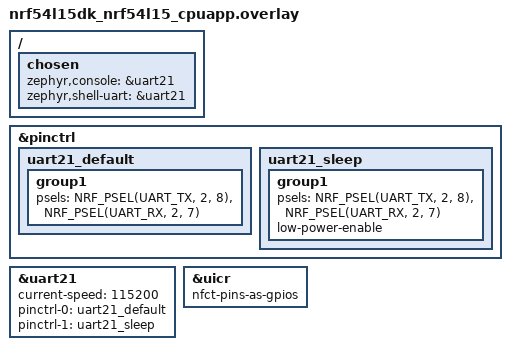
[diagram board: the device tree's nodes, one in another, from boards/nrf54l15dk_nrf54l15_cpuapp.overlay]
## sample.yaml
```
sample:
  description: Hello World sample, the simplest Zephyr
    application
  name: hello world
common:
  min_ram: 2
  min_flash: 16
  tags: introduction
  integration_platforms:
    - native_sim
  harness: console
  harness_config:
    type: one_line
    regex:
      - "Hello World! (.*)"

tests:
  sample.basic.helloworld:
    tags: introduction
```

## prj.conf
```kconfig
# Enable system event API for Constant Latency mode
CONFIG_NRF_SYS_EVENT=y

# Enable UART console
CONFIG_CONSOLE=y
CONFIG_UART_CONSOLE=y
CONFIG_SERIAL=y
```

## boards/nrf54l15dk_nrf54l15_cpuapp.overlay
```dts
/ {
    /* 修改console指向uart21 */
    chosen {
        zephyr,console = &uart21;
        zephyr,shell-uart = &uart21;
    };
};

&pinctrl {
    uart21_default: uart21_default {
        group1 {
            psels = <NRF_PSEL(UART_TX, 2, 8)>,
                    <NRF_PSEL(UART_RX, 2, 7)>;
        };
    };

    uart21_sleep: uart21_sleep {
        group1 {
            psels = <NRF_PSEL(UART_TX, 2, 8)>,
                    <NRF_PSEL(UART_RX, 2, 7)>;
            low-power-enable;
        };
    };
};

&uart21 {
    status = "okay";
    current-speed = <115200>;
    pinctrl-names = "default", "sleep";
    pinctrl-0 = <&uart21_default>;
    pinctrl-1 = <&uart21_sleep>;
};

&uicr {
    nfct-pins-as-gpios;
};
```

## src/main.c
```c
/*
 * Copyright (c) 2012-2014 Wind River Systems, Inc.
 *
 * SPDX-License-Identifier: Apache-2.0
 */

#include <stdio.h>

#include <zephyr/kernel.h>
int main(void)
{
	printf("Hello World! %s\n", CONFIG_BOARD_TARGET);

	while (1) {
		k_yield();
	};

	return 0;
}
```
